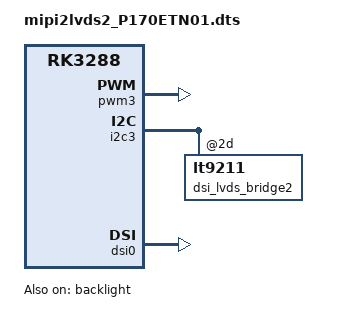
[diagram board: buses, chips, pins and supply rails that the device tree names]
/dts-v1/;
/plugin/;
/ {
	compatible = "rockchip,rk3288-evb-rk808-linux", "rockchip,rk3288";

	fragment@0 {
		target = <&pwm3>;
		__overlay__ {
			status = "okay";
		};
	};
	fragment@1 {
		target = <&backlight>;
		__overlay__ {
			status = "okay";
			pwms = <&pwm3 0 500000 0>;
			minimal-brightness-level = <30>;
			brightness-levels = <
					255 254 253 252 251 250 249 248
					247 246 245 244 243 242 241 240
					239 238 237 236 235 234 233 232
					231 230 229 228 227 226 225 224
					223 222 221 220 219 218 217 216
					215 214 213 212 211 210 209 208
					207 206 205 204 203 202 201 200
					199 198 197 196 195 194 193 192
					191 190 189 188 187 186 185 184
					183 182 181 180 179 178 177 176
					175 174 173 172 171 170 169 168
					167 166 165 164 163 162 161 160
					159 158 157 156 155 154 153 152
					151 150 149 148 147 146 145 144
					143 142 141 140 139 138 137 136
					135 134 133 132 131 130 129 128
					127 126 125 124 123 122 121 120
					119 118 117 116 115 114 113 112
					111 110 109 108 107 106 105 104
					103 102 101 100  99  98  97  96
					95  94  93  92  91  90  89  88
					87  86  85  84  83  82  81  80
					79  78  77  76  75  74  73  72
					71  70  69  68  67  66  65  64
					63  62  61  60  59  58  57  56
					55  54  53  52  51  50  49  48
					47  46  45  44  43  42  41  40
					39  38  37  36  35  34  33  32
					31  30  29  28  27  26  25  24
					23  22  21  20  19  18  17  16
					15  14  13  12  11  10   9   8
					7   6   5   4   3   2    2   0>;
		};
	};
	fragment@2 {
		target = <&i2c3>;
		__overlay__ {
			status = "okay";
			dsi_lvds_bridge2: lt9211@2d {
				status = "okay";
				lvds-format = <2>;//VESA
				lvds-bpp = <24>;
				lvds-width-mm = <358>;
				lvds-height-mm = <296>;
				dual-link;
				de-mode;
				//test-pattern;

				t1=<30>;//VCC on to start lvds signal
				t2=<600>;//LVDS signal(start) to turn Backlihgt on
				t3=<250>;//Backlihgt(off) to stop lvds signal
				t4=<0>;//LVDS signal to turn VCC off
				t5=<1000>;//VCC off to turn VCC on

				width-mm = <358>;
				height-mm = <296>;
				bpc=<8>;
				bus-format = <0x100a>;//<MEDIA_BUS_FMT_RGB888_1X24>;
				dsi,flags = <0x3>;
				dsi,format = <0>;
				dsi,lanes = <2>;

				display-timings {
					lvds {
						clock-frequency = <75000000>;
						hactive = <1280>;
						vactive = <1024>;
						hfront-porch = <72>;
						hback-porch = <72>;
						hsync-len = <36>;
						vfront-porch = <5>;
						vsync-len = <2>;
						vback-porch = <5>;
						hsync-active = <0>;
						vsync-active = <0>;
						de-active = <1>;
						pixelclk-active = <0>;
					};
				};
			};
		};
	};
	fragment@3 {
		target = <&dsi0>;
		__overlay__ {
			status = "okay";
			rockchip,lane-rate=<920>;
			mipi_panel: mipi-panel {
				status = "disabled";
			};
		};
	};
	fragment@4 {
		target = <&pinctrl>;
		__overlay__ {
			gpio_init_config {
				gpio_init: gpio-init {
                    rockchip,pins = <7 22 3 &pcfg_pull_none>;
				};
			};
		};
	};
};
